VERSION "HIPBNYYYYYYYYYYYYYYYYYYYYYYYYYYYNNNNNNNNNN/4/%%%/4/'%**4NNN///"

NS_ :

BS_:

BU_: FR_TESTER TESTER

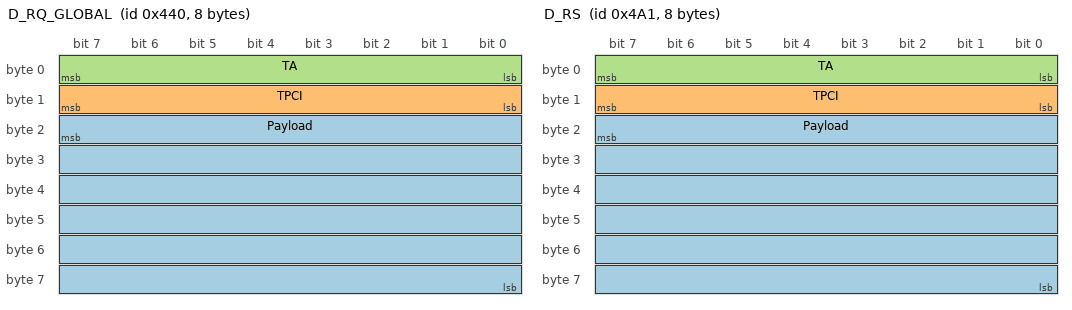
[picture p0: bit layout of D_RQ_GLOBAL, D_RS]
BO_ 1088 D_RQ_GLOBAL: 8 TESTER
 SG_ Payload : 23|48@0+ (1,0) [0|0] "" Vector__XXX
 SG_ TPCI : 15|8@0+ (1,0) [0|0] "" Vector__XXX
 SG_ TA : 7|8@0+ (1,0) [0|0] "" Vector__XXX

BO_ 1185 D_RS: 8 TESTER
 SG_ Payload : 23|48@0+ (1,0) [0|0] "" Vector__XXX
 SG_ TPCI : 15|8@0+ (1,0) [0|0] "" Vector__XXX
 SG_ TA : 7|8@0+ (1,0) [0|0] "" Vector__XXX

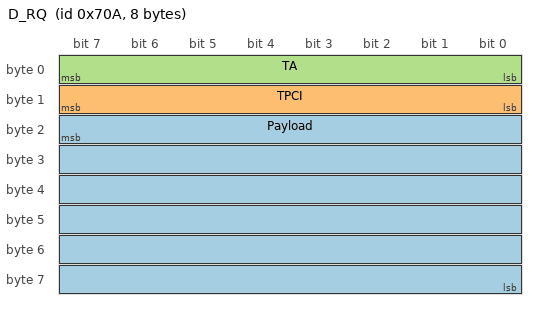
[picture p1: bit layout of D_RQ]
BO_ 1802 D_RQ: 8 TESTER
 SG_ Payload : 23|48@0+ (1,0) [0|0] ""  FR_TESTER,TESTER
 SG_ TPCI : 15|8@0+ (1,0) [0|0] ""  FR_TESTER,TESTER
 SG_ TA : 7|8@0+ (1,0) [0|0] ""  FR_TESTER,TESTER

BO_TX_BU_ 1088 : FR_TESTER,TESTER;
BO_TX_BU_ 1185 : FR_TESTER,TESTER;
BO_TX_BU_ 1802 : FR_TESTER,TESTER;

EV_ ENV_Dump_EEPROM: 0 [0|1] "" 0 1 DUMMY_NODE_VECTOR0 Vector__XXX;

EV_ Env_error_free_switch: 0 [0|1] "" 0 2 DUMMY_NODE_VECTOR0 Vector__XXX;

EV_ Env_Security_Dynamic_Unlock: 0 [0|1] "" 0 3 DUMMY_NODE_VECTOR0 Vector__XXX;

EV_ Env_Security_DynamicInput: 0 [0|0] "" 0 4 DUMMY_NODE_VECTOR8000 Vector__XXX;

EV_ Dynamic_Unlock: 0 [0|1] "" 0 5 DUMMY_NODE_VECTOR0 Vector__XXX;

EV_ Env_MPC3_Manual_Calibration: 0 [0|1] "" 0 6 DUMMY_NODE_VECTOR0 Vector__XXX;

EV_ Env_XPENG_EOL_unlock: 0 [0|1] "" 0 7 DUMMY_NODE_VECTOR0 Vector__XXX;

EV_ Env_TxData_1: 0 [0|0] "" 0 8 DUMMY_NODE_VECTOR3 Vector__XXX;

EV_ Env_ActPMode_2: 0 [0|1] "" 0 9 DUMMY_NODE_VECTOR0 Vector__XXX;

EV_ Env_ActPMode_1: 0 [0|1] "" 0 10 DUMMY_NODE_VECTOR0 Vector__XXX;

EV_ Env_Doip_SecurityMode_Output: 0 [0|0] "" 0 11 DUMMY_NODE_VECTOR8000 Vector__XXX;

EV_ Env_Doip_Security_SeedOutput: 0 [0|0] "" 0 12 DUMMY_NODE_VECTOR8000 Vector__XXX;

EV_ Env_Doip_Security_SubFunction: 0 [0|0] "" 0 13 DUMMY_NODE_VECTOR0 Vector__XXX;

EV_ Env_MPC3_EOL_unlock: 0 [0|1] "" 0 14 DUMMY_NODE_VECTOR0 Vector__XXX;

EV_ EnvDirectSend_2: 0 [0|0] "" 0 15 DUMMY_NODE_VECTOR8000 Vector__XXX;

EV_ EnvMidName: 0 [0|0] "" 0 16 DUMMY_NODE_VECTOR8000 Vector__XXX;

EV_ EnvLogInLevel2: 0 [0|1] "" 0 17 DUMMY_NODE_VECTOR0 Vector__XXX;

EV_ EnvLogInLevel1: 0 [0|1] "" 0 18 DUMMY_NODE_VECTOR0 Vector__XXX;

EV_ EnvFilePathODX: 0 [0|0] "" 0 19 DUMMY_NODE_VECTOR8000 Vector__XXX;

EV_ EnvActPMode: 0 [0|1] "" 0 20 DUMMY_NODE_VECTOR0 Vector__XXX;

EV_ EnvTransmitDataODX: 1 [0|0] "" 0 21 DUMMY_NODE_VECTOR0 Vector__XXX;

EV_ EnvWriteLoginKey: 0 [0|0] "" 0 22 DUMMY_NODE_VECTOR0 Vector__XXX;

EV_ EnvLogInReprogWriteKey: 0 [0|1] "" 0 23 DUMMY_NODE_VECTOR0 Vector__XXX;

EV_ EnvProjectSwitch: 0 [0|1] "" 0 24 DUMMY_NODE_VECTOR0 Vector__XXX;

EV_ EnvMinicode_Dev: 0 [0|1] "" 0 25 DUMMY_NODE_VECTOR0 Vector__XXX;

EV_ EnvMinicode_Plant: 0 [0|1] "" 0 26 DUMMY_NODE_VECTOR0 Vector__XXX;

EV_ Env_Diagnose_01_Umgebungsdaten_a: 0 [0|1] "" 0 27 DUMMY_NODE_VECTOR0 Vector__XXX;

EV_ Env_StartDSDLTest: 0 [0|1] "" 0 28 DUMMY_NODE_VECTOR0 Vector__XXX;

EV_ EnvDtcNr_dec: 0 [0|0] "" 0 29 DUMMY_NODE_VECTOR3 Vector__XXX;

EV_ EnvReprogLoginValue: 0 [0|16777215] "" 10071975 30 DUMMY_NODE_VECTOR0 Vector__XXX;

EV_ EnvDevLoginValue: 0 [0|16777215] "" 89687 31 DUMMY_NODE_VECTOR0 Vector__XXX;

EV_ EnvWerkstattLoginValue: 0 [0|16777215] "" 20103 32 DUMMY_NODE_VECTOR0 Vector__XXX;

EV_ EnvRBEOLLoginValue: 0 [0|16777215] "" 771224 33 DUMMY_NODE_VECTOR0 Vector__XXX;

EV_ EnvWerkstattKey: 0 [0|0] "" 0 34 DUMMY_NODE_VECTOR3 Vector__XXX;

EV_ EnvWerkstattSeed: 0 [0|0] "" 0 35 DUMMY_NODE_VECTOR3 Vector__XXX;

EV_ EnvDevSeed: 0 [0|0] "" 0 36 DUMMY_NODE_VECTOR3 Vector__XXX;

EV_ EnvDevKey: 0 [0|0] "" 0 37 DUMMY_NODE_VECTOR3 Vector__XXX;

EV_ Env_SendBapMsg: 0 [0|0] "" 0 38 DUMMY_NODE_VECTOR0 Vector__XXX;

EV_ EnvFilePath: 0 [0|0] "" 0 39 DUMMY_NODE_VECTOR8000 Vector__XXX;

EV_ Env_GetLaneDetectedRes: 0 [0|1] "" 0 40 DUMMY_NODE_VECTOR0 Vector__XXX;

EV_ Env_GetLaneDetected: 0 [0|1] "" 0 41 DUMMY_NODE_VECTOR0 Vector__XXX;

EV_ EnvDtcLookForInEm: 0 [0|0] "" 0 42 DUMMY_NODE_VECTOR8000 Vector__XXX;

EV_ EnvDtcInEmPresent: 0 [0|1] "" 0 43 DUMMY_NODE_VECTOR0 Vector__XXX;

EV_ Env_Get_Signal_NotNull_Result: 0 [0|0] "" 0 44 DUMMY_NODE_VECTOR8000 Vector__XXX;

EV_ Env_Get_Signal_NotNull: 0 [0|0] "" 0 45 DUMMY_NODE_VECTOR8000 Vector__XXX;

EV_ Env_Get_Signal_Result: 0 [0|0] "" 0 46 DUMMY_NODE_VECTOR8000 Vector__XXX;

EV_ Env_Get_Signal: 0 [0|0] "" 0 47 DUMMY_NODE_VECTOR8000 Vector__XXX;

EV_ Put_Coding_Value_DPC: 0 [0|0] "" 0 48 DUMMY_NODE_VECTOR0 Vector__XXX;

EV_ Get_Coding_Value_DPC: 0 [0|0] "" 0 49 DUMMY_NODE_VECTOR0 Vector__XXX;

EV_ EnvCCPIni: 0 [0|1] "" 0 50 DUMMY_NODE_VECTOR0 Vector__XXX;

EV_ EnvCF_FalsePCIon: 0 [0|1] "" 0 51 DUMMY_NODE_VECTOR0 Vector__XXX;

EV_ EnvCF_PCIValue: 0 [0|0] "" 0 52 DUMMY_NODE_VECTOR0 Vector__XXX;

EV_ EnvCFDelay: 0 [0|0] "" 0 53 DUMMY_NODE_VECTOR0 Vector__XXX;

EV_ EnvCFDoubleDelay: 0 [0|0] "" 0 54 DUMMY_NODE_VECTOR0 Vector__XXX;

EV_ EnvVoltageStep: 1 [-10|10] "" 0 55 DUMMY_NODE_VECTOR0 Vector__XXX;

EV_ EnvVoltageOnOff: 0 [0|1] "" 0 56 DUMMY_NODE_VECTOR0 Vector__XXX;

EV_ EnvVoltageChangeTime: 0 [0|0] "" 0 57 DUMMY_NODE_VECTOR0 Vector__XXX;

EV_ EnvStartupVoltage: 1 [0|30] "" 0 58 DUMMY_NODE_VECTOR0 Vector__XXX;

EV_ EnvStartSim: 0 [0|1] "" 0 59 DUMMY_NODE_VECTOR0 Vector__XXX;

EV_ EnvSpannung2: 0 [0|1] "" 0 60 DUMMY_NODE_VECTOR0 Vector__XXX;

EV_ EnvSpannung: 0 [0|1] "" 0 61 DUMMY_NODE_VECTOR0 Vector__XXX;

EV_ EnvSID: 0 [0|255] "" 0 62 DUMMY_NODE_VECTOR0 Vector__XXX;

EV_ EnvSend: 0 [0|1] "" 0 63 DUMMY_NODE_VECTOR0 Vector__XXX;

EV_ EnvRemoteControl: 0 [0|1] "" 0 64 DUMMY_NODE_VECTOR0 Vector__XXX;

EV_ EnvRDID04: 0 [0|255] "" 0 65 DUMMY_NODE_VECTOR0 Vector__XXX;

EV_ EnvRDID03: 0 [0|255] "" 0 66 DUMMY_NODE_VECTOR0 Vector__XXX;

EV_ EnvRDID02: 0 [0|255] "" 0 67 DUMMY_NODE_VECTOR0 Vector__XXX;

EV_ EnvRDID01: 0 [0|255] "" 0 68 DUMMY_NODE_VECTOR0 Vector__XXX;

EV_ EnvOutput2Value: 1 [0|50] "" 0 69 DUMMY_NODE_VECTOR0 Vector__XXX;

EV_ EnvOutput2: 0 [0|1] "" 0 70 DUMMY_NODE_VECTOR0 Vector__XXX;

EV_ EnvOutput1Value: 1 [0|80] "" 0 71 DUMMY_NODE_VECTOR0 Vector__XXX;

EV_ EnvOutput1: 0 [0|1] "" 0 72 DUMMY_NODE_VECTOR0 Vector__XXX;

EV_ EnvLaenge: 0 [0|255] "" 0 73 DUMMY_NODE_VECTOR0 Vector__XXX;

EV_ EnvGPIBid: 0 [0|65535] "" 0 74 DUMMY_NODE_VECTOR0 Vector__XXX;

EV_ EnvFinalVoltage: 1 [0|30] "" 0 75 DUMMY_NODE_VECTOR0 Vector__XXX;

EV_ InitPhaseTrigger: 0 [0|0] "" 0 76 DUMMY_NODE_VECTOR0 Vector__XXX;

EV_ EnvCommTest_CAN: 0 [0|1] "" 0 77 DUMMY_NODE_VECTOR0 Vector__XXX;

EV_ EnvReadErrorMoreThan_Can: 0 [0|0] "" 0 78 DUMMY_NODE_VECTOR0 Vector__XXX;

EV_ EnvReadErrorLessThan_Can: 0 [0|0] "" 0 79 DUMMY_NODE_VECTOR0 Vector__XXX;

EV_ EnvSetReadDTC: 0 [0|0] "" 0 80 DUMMY_NODE_VECTOR8000 Vector__XXX;

EV_ EnvLogInReprog: 0 [0|1] "" 0 81 DUMMY_NODE_VECTOR0 Vector__XXX;

EV_ EnvPutTimer: 0 [0|0] "" 0 82 DUMMY_NODE_VECTOR0 Vector__XXX;

EV_ EnvRBEOL: 0 [0|1] "" 0 83 DUMMY_NODE_VECTOR0 Vector__XXX;

EV_ EnvRBEOLSeed: 0 [0|0] "" 0 84 DUMMY_NODE_VECTOR3 Vector__XXX;

EV_ EnvRBEOLKey: 0 [0|0] "" 0 85 DUMMY_NODE_VECTOR3 Vector__XXX;

EV_ EnvBVSDPC_Value: 0 [1793|2047] "" 1914 86 DUMMY_NODE_VECTOR0 Vector__XXX;

EV_ EnvLogIn106A3: 0 [0|1] "" 0 87 DUMMY_NODE_VECTOR0 Vector__XXX;

EV_ EnvLogIn4E87: 0 [0|1] "" 0 88 DUMMY_NODE_VECTOR0 Vector__XXX;

EV_ EnvDirectReceive: 0 [0|0] "" 0 89 DUMMY_NODE_VECTOR8000 Vector__XXX;

EV_ EnvErrValueOutput: 0 [0|0] "" 0 90 DUMMY_NODE_VECTOR8000 Vector__XXX;

EV_ EnvFunctionalAddressing: 0 [0|1] "" 0 91 DUMMY_NODE_VECTOR0 Vector__XXX;

EV_ EnvReadPassiveErrors: 0 [0|1] "-" 0 92 DUMMY_NODE_VECTOR3 Vector__XXX;

EV_ EnvDirectReceive_CAN: 0 [0|0] "" 0 93 DUMMY_NODE_VECTOR8000 Vector__XXX;

EV_ EnvClearBuffer_CAN: 0 [0|1] "-" 0 94 DUMMY_NODE_VECTOR3 Vector__XXX;

EV_ EnvReqStatus_Fr: 0 [0|0] "" 0 95 DUMMY_NODE_VECTOR8003 Vector__XXX;

EV_ EnvRxDataLen_Fr: 0 [0|0] "" 0 96 DUMMY_NODE_VECTOR0 Vector__XXX;

EV_ EnvRxData_Fr: 0 [0|0] "" 0 97 DUMMY_NODE_VECTOR3 Vector__XXX;

EV_ EnvDiagTxDefaultValues: 0 [0|48] "-" 0 98 DUMMY_NODE_VECTOR0 Vector__XXX;

EV_ EnvBVSDPC: 0 [0|0] "" 0 99 DUMMY_NODE_VECTOR0 Vector__XXX;

EV_ EnvDtcNr_BVS: 0 [0|0] "" 0 100 DUMMY_NODE_VECTOR8000 Vector__XXX;

EV_ EnvDiagSession: 0 [0|1] "-" 0 101 DUMMY_NODE_VECTOR3 Vector__XXX;

EV_ EnvTesterPresentOnOff: 0 [0|1] "" 0 102 DUMMY_NODE_VECTOR0 Vector__XXX;

EV_ EnvSendBufferFR_1: 0 [0|1] "" 0 103 DUMMY_NODE_VECTOR3 Vector__XXX;

EV_ EnvGetRqRoutineResByLId: 0 [0|0] "" 0 104 DUMMY_NODE_VECTOR0 Vector__XXX;

EV_ EnvRqRoutineResByLIdDisplay: 0 [0|0] "" 0 105 DUMMY_NODE_VECTOR8000 Vector__XXX;

EV_ EnvRqRoutineResByLId: 0 [0|0] "" 43 106 DUMMY_NODE_VECTOR0 Vector__XXX;

EV_ EnvHistEnvDataDisplay: 0 [0|0] "" 0 107 DUMMY_NODE_VECTOR8000 Vector__XXX;

EV_ EnvEnvDataDisplay: 0 [0|0] "" 0 108 DUMMY_NODE_VECTOR8000 Vector__XXX;

EV_ EnvHistDtcNr: 0 [0|0] "" 0 109 DUMMY_NODE_VECTOR8003 Vector__XXX;

EV_ EnvHistDtcPosition: 0 [0|0] "" 0 110 DUMMY_NODE_VECTOR8003 Vector__XXX;

EV_ EnvHistDtcState: 0 [0|0] "" 0 111 DUMMY_NODE_VECTOR8003 Vector__XXX;

EV_ EnvHistDtcName: 0 [0|0] "" 0 112 DUMMY_NODE_VECTOR8003 Vector__XXX;

EV_ EnvHistDtcCountDown: 0 [0|0] "" 0 113 DUMMY_NODE_VECTOR0 Vector__XXX;

EV_ EnvHistDtcCountUp: 0 [0|0] "" 0 114 DUMMY_NODE_VECTOR0 Vector__XXX;

EV_ EnvHistEnvData: 0 [0|0] "" 0 115 DUMMY_NODE_VECTOR0 Vector__XXX;

EV_ EnvClearHistErrors: 0 [0|0] "" 0 116 DUMMY_NODE_VECTOR0 Vector__XXX;

EV_ EnvReadHistErrors: 0 [0|0] "" 0 117 DUMMY_NODE_VECTOR0 Vector__XXX;

EV_ EnvReadRAMResponse: 1 [0|0] "" 0 118 DUMMY_NODE_VECTOR0 Vector__XXX;

EV_ EnvReadRAM: 0 [0|0] "" 0 119 DUMMY_NODE_VECTOR8000 Vector__XXX;

EV_ Env_TCSTART_Testautomation: 0 [0|1] "" 0 120 DUMMY_NODE_VECTOR0 Vector__XXX;

EV_ Env_TC_Two_RES: 0 [0|2] "" 0 121 DUMMY_NODE_VECTOR0 Vector__XXX;

EV_ Env_TC_Two_Act: 0 [0|1] "" 1 122 DUMMY_NODE_VECTOR0 Vector__XXX;

EV_ Env_TC_Three_RES: 0 [0|2] "" 0 123 DUMMY_NODE_VECTOR0 Vector__XXX;

EV_ Env_TC_Three_Act: 0 [0|1] "" 1 124 DUMMY_NODE_VECTOR0 Vector__XXX;

EV_ Env_TC_Six_RES: 0 [0|2] "" 0 125 DUMMY_NODE_VECTOR0 Vector__XXX;

EV_ Env_TC_Six_Act: 0 [0|1] "" 1 126 DUMMY_NODE_VECTOR0 Vector__XXX;

EV_ Env_TC_Seven_RES: 0 [0|2] "" 0 127 DUMMY_NODE_VECTOR0 Vector__XXX;

EV_ Env_TC_Seven_Act: 0 [0|1] "" 1 128 DUMMY_NODE_VECTOR0 Vector__XXX;

EV_ Env_TC_RES_Statistics2: 0 [0|1] "" 0 129 DUMMY_NODE_VECTOR0 Vector__XXX;

EV_ Env_TC_One_RES: 0 [0|2] "" 0 130 DUMMY_NODE_VECTOR0 Vector__XXX;

EV_ Env_TC_One_Act: 0 [0|1] "" 1 131 DUMMY_NODE_VECTOR0 Vector__XXX;

EV_ Env_TC_Nine_RES: 0 [0|2] "" 0 132 DUMMY_NODE_VECTOR0 Vector__XXX;

EV_ Env_TC_Nine_Act: 0 [0|1] "" 1 133 DUMMY_NODE_VECTOR0 Vector__XXX;

EV_ Env_TC_Four_RES: 0 [0|2] "" 0 134 DUMMY_NODE_VECTOR0 Vector__XXX;

EV_ Env_TC_Four_Act: 0 [0|1] "" 1 135 DUMMY_NODE_VECTOR0 Vector__XXX;

EV_ Env_TC_Five_RES: 0 [0|2] "" 0 136 DUMMY_NODE_VECTOR0 Vector__XXX;

EV_ Env_TC_Five_Act: 0 [0|1] "" 1 137 DUMMY_NODE_VECTOR0 Vector__XXX;

EV_ Env_TC_Eight_RES: 0 [0|2] "" 0 138 DUMMY_NODE_VECTOR0 Vector__XXX;

EV_ Env_TC_Eight_Act: 0 [0|1] "" 1 139 DUMMY_NODE_VECTOR0 Vector__XXX;

EV_ EnvPC_Variant: 0 [0|191] "" 0 140 DUMMY_NODE_VECTOR0 Vector__XXX;

EV_ EnvFlexType: 0 [0|0] "-" 0 141 DUMMY_NODE_VECTOR8003 Vector__XXX;

EV_ EnvExecBatch: 0 [0|1] "" 0 142 DUMMY_NODE_VECTOR3 Vector__XXX;

EV_ EnvTransfer: 0 [0|0] "" 0 143 DUMMY_NODE_VECTOR0 Vector__XXX;

EV_ EnvRAMWrite: 0 [0|0] "" 0 144 DUMMY_NODE_VECTOR8000 Vector__XXX;

EV_ EnvRAMResponse: 0 [0|0] "" 0 145 DUMMY_NODE_VECTOR8000 Vector__XXX;

EV_ EnvRAMReadout: 0 [0|0] "" 0 146 DUMMY_NODE_VECTOR8000 Vector__XXX;

EV_ EnvNrNeededRespBytes: 0 [0|80] "" 0 147 DUMMY_NODE_VECTOR0 Vector__XXX;

EV_ EnvDirectSendInit: 0 [0|1] "" 0 148 DUMMY_NODE_VECTOR0 Vector__XXX;

EV_ Env_TCSTART_Variant: 0 [0|1] "" 0 149 DUMMY_NODE_VECTOR0 Vector__XXX;

EV_ Env_TCRES_WrongSignal: 0 [0|1] "" 0 150 DUMMY_NODE_VECTOR0 Vector__XXX;

EV_ Env_TCRES_Thresholds: 0 [0|1] "" 0 151 DUMMY_NODE_VECTOR0 Vector__XXX;

EV_ Env_TCRES_Statistics: 0 [0|1] "" 0 152 DUMMY_NODE_VECTOR0 Vector__XXX;

EV_ Env_TCRES_Pseudocolor: 0 [0|1] "" 0 153 DUMMY_NODE_VECTOR0 Vector__XXX;

EV_ Env_TCRES_NoVariant: 0 [0|1] "" 0 154 DUMMY_NODE_VECTOR0 Vector__XXX;

EV_ Env_TCRES_ImgProc: 0 [0|1] "" 0 155 DUMMY_NODE_VECTOR0 Vector__XXX;

EV_ Env_TCRES_HeadLightPattern: 0 [0|1] "" 0 156 DUMMY_NODE_VECTOR0 Vector__XXX;

EV_ Env_TCRES_Calibration: 0 [0|1] "" 0 157 DUMMY_NODE_VECTOR0 Vector__XXX;

EV_ EnvNoDirectRq: 0 [0|4] "" 2 158 DUMMY_NODE_VECTOR0 Vector__XXX;

EV_ EnvDirectSend: 0 [0|0] "" 0 159 DUMMY_NODE_VECTOR8000 Vector__XXX;

EV_ EnvCalibDown: 0 [0|0] "" 0 160 DUMMY_NODE_VECTOR0 Vector__XXX;

EV_ EnvCalibUp: 0 [0|0] "" 0 161 DUMMY_NODE_VECTOR0 Vector__XXX;

EV_ EnvCalibRight: 0 [0|0] "" 0 162 DUMMY_NODE_VECTOR0 Vector__XXX;

EV_ EnvCalibLeft: 0 [0|0] "" 0 163 DUMMY_NODE_VECTOR0 Vector__XXX;

EV_ EnvCalibDel: 0 [0|0] "" 0 164 DUMMY_NODE_VECTOR0 Vector__XXX;

EV_ EnvCalibSave: 0 [0|0] "" 0 165 DUMMY_NODE_VECTOR0 Vector__XXX;

EV_ EnvMaxSearchTime: 0 [0|0] "" 0 166 DUMMY_NODE_VECTOR0 Vector__XXX;

EV_ EnvMaxRoll: 1 [0|0] "" 0 167 DUMMY_NODE_VECTOR0 Vector__XXX;

EV_ EnvMaxYaw: 1 [0|0] "" 0 168 DUMMY_NODE_VECTOR0 Vector__XXX;

EV_ EnvMaxPitch: 1 [0|0] "" 0 169 DUMMY_NODE_VECTOR0 Vector__XXX;

EV_ EnvCalibAuto: 0 [0|0] "" 0 170 DUMMY_NODE_VECTOR0 Vector__XXX;

EV_ EnvCrapAngle: 1 [0|0] "" 0 171 DUMMY_NODE_VECTOR0 Vector__XXX;

EV_ EnvFC_FalsePCIon: 0 [0|0] "" 0 172 DUMMY_NODE_VECTOR0 Vector__XXX;

EV_ EnvFC_PCIValue: 0 [0|0] "" 0 173 DUMMY_NODE_VECTOR0 Vector__XXX;

EV_ EnvCFNr: 0 [1|255] "" 1 174 DUMMY_NODE_VECTOR0 Vector__XXX;

EV_ EnvFCNr: 0 [0|0] "" 0 175 DUMMY_NODE_VECTOR0 Vector__XXX;

EV_ EnvFCDoubleOn: 0 [0|1] "" 0 176 DUMMY_NODE_VECTOR0 Vector__XXX;

EV_ EnvCFDrop: 0 [0|0] "" 0 177 DUMMY_NODE_VECTOR0 Vector__XXX;

EV_ EnvWaitingState: 0 [0|0] "" 0 178 DUMMY_NODE_VECTOR0 Vector__XXX;

EV_ EnvFCDelay: 0 [0|0] "" 0 179 DUMMY_NODE_VECTOR0 Vector__XXX;

EV_ EnvECUAdress: 0 [0|0] "" 0 180 DUMMY_NODE_VECTOR0 Vector__XXX;

EV_ EnvUseFC: 0 [0|1] "" 1 181 DUMMY_NODE_VECTOR0 Vector__XXX;

EV_ EnvCAN: 0 [0|10] "" 1 182 DUMMY_NODE_VECTOR0 Vector__XXX;

EV_ EnvDllTxId: 0 [0|2031] "" 1874 183 DUMMY_NODE_VECTOR0 Vector__XXX;

EV_ EnvDllSTMin: 0 [0|255] "" 20 184 DUMMY_NODE_VECTOR3 Vector__XXX;

EV_ EnvDllRxId: 0 [0|2031] "" 1882 185 DUMMY_NODE_VECTOR0 Vector__XXX;

EV_ EnvDllBlockSize: 0 [0|255] "" 8 186 DUMMY_NODE_VECTOR0 Vector__XXX;

EV_ EnvRxDataLen_CAN: 0 [0|0] "" 0 187 DUMMY_NODE_VECTOR0 Vector__XXX;

EV_ EnvRdDataByLIdDisplay: 0 [0|0] "" 0 188 DUMMY_NODE_VECTOR8000 Vector__XXX;

EV_ EnvGetRdDataByLId: 0 [0|0] "" 0 189 DUMMY_NODE_VECTOR0 Vector__XXX;

EV_ EnvReadDataByLId: 0 [0|0] "" 35 190 DUMMY_NODE_VECTOR0 Vector__XXX;

EV_ EnvShowSysRuntime: 0 [0|0] "" 0 191 DUMMY_NODE_VECTOR0 Vector__XXX;

EV_ EnvEngInfo: 0 [0|0] "" 0 192 DUMMY_NODE_VECTOR0 Vector__XXX;

EV_ EnvSysRuntime: 0 [0|0] "" 0 193 DUMMY_NODE_VECTOR0 Vector__XXX;

EV_ EnvRomParVerHB: 0 [0|0] "" 0 194 DUMMY_NODE_VECTOR8000 Vector__XXX;

EV_ EnvRomParVerLB: 0 [0|0] "" 0 195 DUMMY_NODE_VECTOR8000 Vector__XXX;

EV_ EnvParVer: 0 [0|0] "" 0 196 DUMMY_NODE_VECTOR8000 Vector__XXX;

EV_ EnvVehicle: 0 [0|0] "" 0 197 DUMMY_NODE_VECTOR8000 Vector__XXX;

EV_ EnvHwSubVer: 0 [0|0] "" 0 198 DUMMY_NODE_VECTOR8000 Vector__XXX;

EV_ EnvHwMainVer: 0 [0|0] "" 0 199 DUMMY_NODE_VECTOR8000 Vector__XXX;

EV_ EnvSwSubVer: 0 [0|0] "" 0 200 DUMMY_NODE_VECTOR8000 Vector__XXX;

EV_ EnvSwMainVer: 0 [0|0] "" 0 201 DUMMY_NODE_VECTOR8000 Vector__XXX;

EV_ EnvCalib: 0 [0|1] "" 0 202 DUMMY_NODE_VECTOR3 Vector__XXX;

EV_ EnvDay: 0 [0|0] "" 0 203 DUMMY_NODE_VECTOR8000 Vector__XXX;

EV_ EnvSup: 0 [0|0] "" 0 204 DUMMY_NODE_VECTOR8000 Vector__XXX;

EV_ EnvTFZ: 0 [0|0] "" 0 205 DUMMY_NODE_VECTOR8000 Vector__XXX;

EV_ EnvP: 0 [0|0] "" 0 206 DUMMY_NODE_VECTOR8000 Vector__XXX;

EV_ EnvProdYear: 0 [0|0] "" 0 207 DUMMY_NODE_VECTOR8000 Vector__XXX;

EV_ EnvBr: 0 [0|0] "" 0 208 DUMMY_NODE_VECTOR8000 Vector__XXX;

EV_ EnvLeftCamSW: 0 [0|0] "" 0 209 DUMMY_NODE_VECTOR8000 Vector__XXX;

EV_ EnvResetRuntime: 0 [0|0] "" 0 210 DUMMY_NODE_VECTOR0 Vector__XXX;

EV_ EnvEnvData: 0 [0|0] "" 0 211 DUMMY_NODE_VECTOR0 Vector__XXX;

EV_ EnvRightCamSW: 0 [0|0] "" 0 212 DUMMY_NODE_VECTOR8000 Vector__XXX;

EV_ EnvLeftCamCN: 0 [0|0] "" 0 213 DUMMY_NODE_VECTOR8000 Vector__XXX;

EV_ EnvRightCamCN: 0 [0|0] "" 0 214 DUMMY_NODE_VECTOR8000 Vector__XXX;

EV_ EnvLeftCamSN: 0 [0|0] "" 0 215 DUMMY_NODE_VECTOR8000 Vector__XXX;

EV_ EnvRightCamSN: 0 [0|0] "" 0 216 DUMMY_NODE_VECTOR8000 Vector__XXX;

EV_ EnvIrTest: 0 [0|1] "" 0 217 DUMMY_NODE_VECTOR3 Vector__XXX;

EV_ EnvTestPicture: 0 [0|1] "" 0 218 DUMMY_NODE_VECTOR3 Vector__XXX;

EV_ EnvTxData_2: 0 [0|0] "" 0 219 DUMMY_NODE_VECTOR3 Vector__XXX;

EV_ EnvTxData_1: 0 [0|0] "" 0 220 DUMMY_NODE_VECTOR3 Vector__XXX;

EV_ EnvRxData_CAN: 0 [0|0] "" 0 221 DUMMY_NODE_VECTOR3 Vector__XXX;

EV_ EnvBatchSerial: 0 [0|0] "-" 0 222 DUMMY_NODE_VECTOR3 Vector__XXX;

EV_ EnvBatchManuYear: 0 [0|255] "-" 0 223 DUMMY_NODE_VECTOR3 Vector__XXX;

EV_ EnvBatchManuMonth: 0 [0|255] "-" 0 224 DUMMY_NODE_VECTOR3 Vector__XXX;

EV_ EnvBatchManuDay: 0 [0|255] "-" 0 225 DUMMY_NODE_VECTOR3 Vector__XXX;

EV_ EnvDtcName: 0 [0|0] "" 0 226 DUMMY_NODE_VECTOR8003 Vector__XXX;

EV_ EnvDtcState: 0 [0|0] "" 0 227 DUMMY_NODE_VECTOR8003 Vector__XXX;

EV_ EnvDtcPosition: 0 [0|0] "" 0 228 DUMMY_NODE_VECTOR8003 Vector__XXX;

EV_ EnvDtcNr: 0 [0|0] "" 0 229 DUMMY_NODE_VECTOR8003 Vector__XXX;

EV_ EnvDtcCountUp: 0 [0|20] "-" 0 230 DUMMY_NODE_VECTOR3 Vector__XXX;

EV_ EnvDtcCountDown: 0 [0|20] "-" 0 231 DUMMY_NODE_VECTOR3 Vector__XXX;

EV_ EnvTP: 0 [0|0] "-" 0 232 DUMMY_NODE_VECTOR8003 Vector__XXX;

EV_ EnvDevSt: 0 [0|0] "-" 0 233 DUMMY_NODE_VECTOR8003 Vector__XXX;

EV_ EnvProcessor: 0 [0|0] "-" 0 234 DUMMY_NODE_VECTOR8003 Vector__XXX;

EV_ EnvNM: 0 [0|0] "-" 0 235 DUMMY_NODE_VECTOR8003 Vector__XXX;

EV_ EnvKM: 0 [0|0] "-" 0 236 DUMMY_NODE_VECTOR8003 Vector__XXX;

EV_ EnvFlex: 0 [0|0] "-" 0 237 DUMMY_NODE_VECTOR8003 Vector__XXX;

EV_ EnvDiag: 0 [0|0] "-" 0 238 DUMMY_NODE_VECTOR8003 Vector__XXX;

EV_ EnvDBK: 0 [0|0] "-" 0 239 DUMMY_NODE_VECTOR8003 Vector__XXX;

EV_ EnvDrvCan: 0 [0|0] "-" 0 240 DUMMY_NODE_VECTOR8003 Vector__XXX;

EV_ EnvSendBuffer_2: 0 [0|1] "" 0 241 DUMMY_NODE_VECTOR3 Vector__XXX;

EV_ EnvSendBuffer_1: 0 [0|1] "" 0 242 DUMMY_NODE_VECTOR3 Vector__XXX;

EV_ EnvReadErrors: 0 [0|1] "-" 0 243 DUMMY_NODE_VECTOR3 Vector__XXX;

EV_ EnvIdent: 0 [0|1] "-" 0 244 DUMMY_NODE_VECTOR3 Vector__XXX;

EV_ EnvEnableMsg: 0 [0|1] "-" 0 245 DUMMY_NODE_VECTOR3 Vector__XXX;

EV_ EnvDisableMsg: 0 [0|1] "-" 0 246 DUMMY_NODE_VECTOR3 Vector__XXX;

EV_ EnvDiagOnOff: 0 [0|1] "-" 0 247 DUMMY_NODE_VECTOR3 Vector__XXX;

EV_ EnvClearErrors: 0 [0|1] "-" 0 248 DUMMY_NODE_VECTOR3 Vector__XXX;

EV_ EnvBatchStatus: 0 [0|0] "" 0 249 DUMMY_NODE_VECTOR8003 Vector__XXX;

EV_ EnvBatchFile: 0 [0|0] "" 0 250 DUMMY_NODE_VECTOR8003 Vector__XXX;

EV_ EnvEcuSwId: 0 [0|0] "-" 0 251 DUMMY_NODE_VECTOR8003 Vector__XXX;

EV_ EnvSupId: 0 [0|0] "-" 0 252 DUMMY_NODE_VECTOR8003 Vector__XXX;

EV_ EnvEcuSerialNr: 0 [0|0] "-" 0 253 DUMMY_NODE_VECTOR8003 Vector__XXX;

EV_ EnvHwSt: 0 [0|0] "-" 0 254 DUMMY_NODE_VECTOR8003 Vector__XXX;

EV_ EnvProduction: 0 [0|0] "-" 0 255 DUMMY_NODE_VECTOR8003 Vector__XXX;

EV_ EnvDiagStand: 0 [0|0] "-" 0 256 DUMMY_NODE_VECTOR8003 Vector__XXX;

EV_ EnvDcNr: 0 [0|0] "-" 0 257 DUMMY_NODE_VECTOR8003 Vector__XXX;

EV_ EnvReqStatus_CAN: 0 [0|0] "" 0 258 DUMMY_NODE_VECTOR8003 Vector__XXX;

EV_ EnvRespTime_CAN: 1 [0|0] "" 0 259 DUMMY_NODE_VECTOR0 Vector__XXX;

EV_ EnvCamOff: 0 [0|1] "" 0 260 DUMMY_NODE_VECTOR0 Vector__XXX;

EV_ EnvCamOn: 0 [0|1] "" 0 261 DUMMY_NODE_VECTOR0 Vector__XXX;

EV_ EnvExtAgilentVoltage: 1 [0|35] "" 12 262 DUMMY_NODE_VECTOR0 Vector__XXX;

EV_ EnvExtAgilentOnOff: 0 [0|1] "" 1 263 DUMMY_NODE_VECTOR0 Vector__XXX;

EV_ EnvSGAlive: 0 [0|2] "" 0 264 DUMMY_NODE_VECTOR0 Vector__XXX;

EV_ EnvFuncRequest: 0 [0|0] "" 0 265 DUMMY_NODE_VECTOR8000 Vector__XXX;

EV_ EnvQuickCalStatus: 0 [0|0] "" 0 266 DUMMY_NODE_VECTOR8000 Vector__XXX;

EV_ EnvQuickCal: 0 [0|1] "" 0 267 DUMMY_NODE_VECTOR0 Vector__XXX;

EV_ EnvExecuteScript: 0 [0|0] "" 0 268 DUMMY_NODE_VECTOR0 Vector__XXX;

EV_ EnvResultsPath: 0 [0|0] "" 0 269 DUMMY_NODE_VECTOR8003 Vector__XXX;

EV_ EnvScriptPath: 0 [0|0] "" 0 270 DUMMY_NODE_VECTOR8003 Vector__XXX;

EV_ Env_Compare_Signal_Results: 0 [0|0] "" 0 271 DUMMY_NODE_VECTOR8001 Vector__XXX;

EV_ Env_Compare_Signal_2: 0 [0|0] "" 0 272 DUMMY_NODE_VECTOR8001 Vector__XXX;

EV_ Env_Compare_Signal_1: 0 [0|0] "" 0 273 DUMMY_NODE_VECTOR8001 Vector__XXX;

EV_ Env_Get_Signal_Signum_Result: 0 [0|0] "" 0 274 DUMMY_NODE_VECTOR8001 Vector__XXX;

EV_ Env_Get_Signal_Signum: 0 [0|0] "" 0 275 DUMMY_NODE_VECTOR8000 Vector__XXX;

EV_ Env_ShowImage: 0 [0|0] "" 0 276 DUMMY_NODE_VECTOR8000 Vector__XXX;

EV_ Env_Get_Signal_Alter: 0 [0|0] "" 0 277 DUMMY_NODE_VECTOR8000 Vector__XXX;

EV_ Env_Get_Signal_Alter_Result: 0 [0|0] "" 0 278 DUMMY_NODE_VECTOR8000 Vector__XXX;

EV_ Env_Get_Signal_Float: 0 [0|0] "" 0 279 DUMMY_NODE_VECTOR8000 Vector__XXX;

EV_ Env_Get_Signal_Float_Result: 1 [0|0] "" 0 280 DUMMY_NODE_VECTOR0 Vector__XXX;

EV_ Env_SetBrightness: 0 [0|0] "" 0 281 DUMMY_NODE_VECTOR8000 Vector__XXX;

EV_ Env_PAG_ESP_v_Signal_Rv: 0 [0|65532] "" 0 282 DUMMY_NODE_VECTOR0 Vector__XXX;
ENVVAR_DATA_ Env_TxData_1: 100;
ENVVAR_DATA_ Env_Doip_Security_SubFunction: 1;
ENVVAR_DATA_ EnvWerkstattKey: 4;
ENVVAR_DATA_ EnvWerkstattSeed: 4;
ENVVAR_DATA_ EnvDevSeed: 4;
ENVVAR_DATA_ EnvDevKey: 4;
ENVVAR_DATA_ EnvRBEOLSeed: 4;
ENVVAR_DATA_ EnvRBEOLKey: 4;
ENVVAR_DATA_ EnvRxData_Fr: 256;
ENVVAR_DATA_ EnvTxData_2: 0;
ENVVAR_DATA_ EnvTxData_1: 100;
ENVVAR_DATA_ EnvRxData_CAN: 256;

CM_ BU_ FR_TESTER "Test Transportschicht mit DLL";
CM_ BU_ TESTER "Test Transportschicht mit DLL";
BA_DEF_  "BusType" STRING ;
BA_DEF_ BO_  "DiagRequest" ENUM  "no","yes";
BA_DEF_ BO_  "DiagResponse" ENUM  "no","yes";
BA_DEF_ BU_  "TpBlockSize" INT 0 255;
BA_DEF_ BU_  "TpSTMin" INT 0 255;
BA_DEF_ BU_  "TpNodeBaseAddress" HEX 0 33554431;
BA_DEF_ BU_  "TpUseFC" INT 0 1;
BA_DEF_ BU_  "TpCanBus" INT 1 2;
BA_DEF_ BU_  "TpRxMask" HEX 0 65535;
BA_DEF_ BU_  "Diagnose-Stationsadresse" HEX 0 255;
BA_DEF_ BU_  "TpRxIdentifier" HEX 0 536870911;
BA_DEF_ BU_  "TpTxIdentifier" HEX 0 536870911;
BA_DEF_ BU_  "NodeLayerModules" STRING ;
BA_DEF_  "TpBaseAddress" HEX 0 536870911;
BA_DEF_ EV_  "SystemEnvVarLongSymbol" STRING ;
BA_DEF_DEF_  "BusType" "";
BA_DEF_DEF_  "DiagRequest" "no";
BA_DEF_DEF_  "DiagResponse" "no";
BA_DEF_DEF_  "TpBlockSize" 0;
BA_DEF_DEF_  "TpSTMin" 0;
BA_DEF_DEF_  "TpNodeBaseAddress" 1536;
BA_DEF_DEF_  "TpUseFC" 1;
BA_DEF_DEF_  "TpCanBus" 1;
BA_DEF_DEF_  "TpRxMask" 255;
BA_DEF_DEF_  "Diagnose-Stationsadresse" 0;
BA_DEF_DEF_  "TpRxIdentifier" 1185;
BA_DEF_DEF_  "TpTxIdentifier" 1802;
BA_DEF_DEF_  "NodeLayerModules" "osek_tp.dll";
BA_DEF_DEF_  "TpBaseAddress" 1536;
BA_DEF_DEF_  "SystemEnvVarLongSymbol" "";
BA_ "BusType" "CAN";
BA_ "TpBlockSize" BU_ FR_TESTER 2;
BA_ "TpSTMin" BU_ FR_TESTER 20;
BA_ "TpNodeBaseAddress" BU_ FR_TESTER 1792;
BA_ "Diagnose-Stationsadresse" BU_ FR_TESTER 88;
BA_ "TpRxIdentifier" BU_ FR_TESTER 1986;
BA_ "TpTxIdentifier" BU_ FR_TESTER 1880;
BA_ "TpTxIdentifier" BU_ TESTER 1830;
BA_ "TpRxIdentifier" BU_ TESTER 1936;
BA_ "Diagnose-Stationsadresse" BU_ TESTER 38;
BA_ "TpSTMin" BU_ TESTER 20;
BA_ "TpBlockSize" BU_ TESTER 2;
BA_ "TpNodeBaseAddress" BU_ TESTER 1792;
BA_ "DiagRequest" BO_ 1088 1;
BA_ "DiagResponse" BO_ 1185 1;
BA_ "DiagRequest" BO_ 1802 1;
BA_ "SystemEnvVarLongSymbol" EV_ Env_Diagnose_01_Umgebungsdaten_a "Env_Diagnose_01_Umgebungsdaten_auto";
VAL_ EnvDiagTxDefaultValues 6 "ReadDatasetVersion" 5 "ReadDiagnosticSession" 4 "SparePartNumber" 3 "SoftwareVersionNumber" 2 "SupplierSoftwareNumber" 1 "SupplierSoftwareVersionNumber" 0 " " ;
VAL_ EnvRqRoutineResByLId 45 "Selftest Camera" 44 "CheckSum" 43 "Auto Calibration" ;
VAL_ EnvReadDataByLId 35 "Max Calib" 28 "Temp Profile" 27 "ECU St" 26 "Calib Data" 25 "Temp" 24 "CAN Sig" ;
